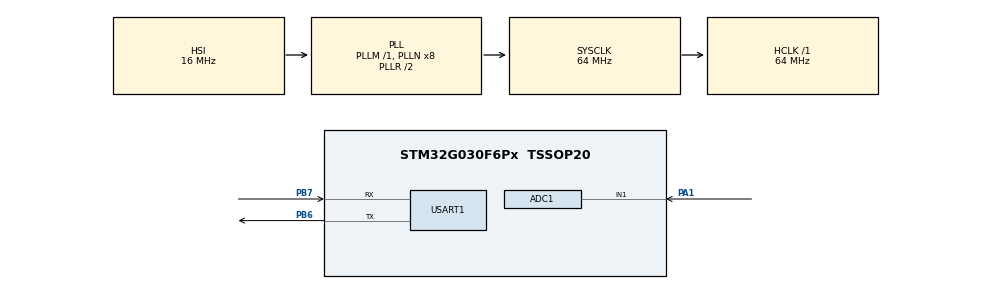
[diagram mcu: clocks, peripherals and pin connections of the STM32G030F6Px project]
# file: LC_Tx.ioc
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ADC1.Channel-2\#ChannelRegularConversion=ADC_CHANNEL_1
ADC1.ContinuousConvMode=ENABLE
ADC1.NbrOfConversionFlag=1
ADC1.Rank-2\#ChannelRegularConversion=1
ADC1.SamplingTime-2\#ChannelRegularConversion=ADC_SAMPLINGTIME_COMMON_1
ADC1.SelectedChannel=ADC_CHANNEL_1
ADC1.master=1
Mcu.Family=STM32G0
Mcu.Name=STM32G030F6Px
Mcu.Package=TSSOP20
PA1.Mode=IN1
PA1.Signal=ADC1_IN1
PA13.Mode=Serial_Wire
PA13.Signal=SYS_SWDIO
PA14-BOOT0.Mode=Serial_Wire
PA14-BOOT0.Signal=SYS_SWCLK
PA14-BOOT0__PA15.StandardMode=true
PB0__PB1__PB2__PA8.StandardMode=true
PB3__PB4__PB5__PB6.StandardMode=true
PB6.Mode=Asynchronous
PB6.Signal=USART1_TX
PB7.Mode=Asynchronous
PB7.Signal=USART1_RX
PB7__PB8.StandardMode=true
PC14-OSC32_IN\ (PC14)__PB9.StandardMode=true
ProjectManager.HeapSize=0x200
ProjectManager.StackSize=0x400
ProjectManager.TargetToolchain=STM32CubeIDE
RCC.ADCFreq_Value=64000000
RCC.AHBFreq_Value=64000000
RCC.CortexFreq_Value=64000000
RCC.EXTERNAL_CLOCK_VALUE=12288000
RCC.HCLKFreq_Value=64000000
RCC.HSE_VALUE=8000000
RCC.HSI_VALUE=16000000
RCC.LSE_VALUE=32768
RCC.SYSCLKFreq_VALUE=64000000
RCC.SYSCLKSource=RCC_SYSCLKSOURCE_PLLCLK
RCC.VCOOutputFreq_Value=128000000
USART1.VirtualMode-Asynchronous=VM_ASYNC
board=custom

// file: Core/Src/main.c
/* USER CODE BEGIN Header */
/**
  ******************************************************************************
  * @file           : main.c
  * @brief          : Main program body
  ******************************************************************************
  * @attention
  *
  * Copyright (c) 2023 STMicroelectronics.
  * All rights reserved.
  *
  * This software is licensed under terms that can be found in the LICENSE file
  * in the root directory of this software component.
  * If no LICENSE file comes with this software, it is provided AS-IS.
  *
  ******************************************************************************
  */
/* USER CODE END Header */
#include "main.h"

ADC_HandleTypeDef hadc1;

UART_HandleTypeDef huart1;

void SystemClock_Config(void);
static void MX_GPIO_Init(void);
static void MX_ADC1_Init(void);
static void MX_USART1_UART_Init(void);

int main(void)
{

  /* MCU Configuration--------------------------------------------------------*/

  /* Reset of all peripherals, Initializes the Flash interface and the Systick. */
  HAL_Init();

  /* Configure the system clock */
  SystemClock_Config();

  /* Initialize all configured peripherals */
  MX_GPIO_Init();
  MX_ADC1_Init();
  MX_USART1_UART_Init();
  /* USER CODE BEGIN 2 */
  HAL_ADCEx_Calibration_Start(&hadc1);
  HAL_ADC_Start(&hadc1);
  /* USER CODE END 2 */

  /* Infinite loop */
  while (1)
  {

    /* USER CODE BEGIN 3 */
//	  uint8_t Test[] = "Hello World !!!\r\n"; //Data to send
//	  HAL_UART_Transmit(&huart1,Test,sizeof(Test),10);// Sending in normal mode
//	  HAL_Delay(500);

	  HAL_ADC_PollForConversion(&hadc1, HAL_MAX_DELAY);
	  uint32_t value_adc = HAL_ADC_GetValue(&hadc1);
	  HAL_UART_Transmit(&huart1,(uint8_t*)&value_adc,sizeof(uint32_t),10);
	  HAL_Delay(100);
  }
  /* USER CODE END 3 */
}

void SystemClock_Config(void)
{
  RCC_OscInitTypeDef RCC_OscInitStruct = {0};
  RCC_ClkInitTypeDef RCC_ClkInitStruct = {0};

  /** Configure the main internal regulator output voltage
  */
  HAL_PWREx_ControlVoltageScaling(PWR_REGULATOR_VOLTAGE_SCALE1);

  /** Initializes the RCC Oscillators according to the specified parameters
  * in the RCC_OscInitTypeDef structure.
  */
  RCC_OscInitStruct.OscillatorType = RCC_OSCILLATORTYPE_HSI;
  RCC_OscInitStruct.HSIState = RCC_HSI_ON;
  RCC_OscInitStruct.HSIDiv = RCC_HSI_DIV1;
  RCC_OscInitStruct.HSICalibrationValue = RCC_HSICALIBRATION_DEFAULT;
  RCC_OscInitStruct.PLL.PLLState = RCC_PLL_ON;
  RCC_OscInitStruct.PLL.PLLSource = RCC_PLLSOURCE_HSI;
  RCC_OscInitStruct.PLL.PLLM = RCC_PLLM_DIV1;
  RCC_OscInitStruct.PLL.PLLN = 8;
  RCC_OscInitStruct.PLL.PLLP = RCC_PLLP_DIV2;
  RCC_OscInitStruct.PLL.PLLR = RCC_PLLR_DIV2;
  if (HAL_RCC_OscConfig(&RCC_OscInitStruct) != HAL_OK)
  {
    Error_Handler();
  }

  /** Initializes the CPU, AHB and APB buses clocks
  */
  RCC_ClkInitStruct.ClockType = RCC_CLOCKTYPE_HCLK|RCC_CLOCKTYPE_SYSCLK
                              |RCC_CLOCKTYPE_PCLK1;
  RCC_ClkInitStruct.SYSCLKSource = RCC_SYSCLKSOURCE_PLLCLK;
  RCC_ClkInitStruct.AHBCLKDivider = RCC_SYSCLK_DIV1;
  RCC_ClkInitStruct.APB1CLKDivider = RCC_HCLK_DIV1;

  if (HAL_RCC_ClockConfig(&RCC_ClkInitStruct, FLASH_LATENCY_2) != HAL_OK)
  {
    Error_Handler();
  }
}

static void MX_ADC1_Init(void)
{

  ADC_ChannelConfTypeDef sConfig = {0};

  /** Configure the global features of the ADC (Clock, Resolution, Data Alignment and number of conversion)
  */
  hadc1.Instance = ADC1;
  hadc1.Init.ClockPrescaler = ADC_CLOCK_SYNC_PCLK_DIV2;
  hadc1.Init.Resolution = ADC_RESOLUTION_12B;
  hadc1.Init.DataAlign = ADC_DATAALIGN_RIGHT;
  hadc1.Init.ScanConvMode = ADC_SCAN_DISABLE;
  hadc1.Init.EOCSelection = ADC_EOC_SINGLE_CONV;
  hadc1.Init.LowPowerAutoWait = DISABLE;
  hadc1.Init.LowPowerAutoPowerOff = DISABLE;
  hadc1.Init.ContinuousConvMode = ENABLE;
  hadc1.Init.NbrOfConversion = 1;
  hadc1.Init.ExternalTrigConv = ADC_SOFTWARE_START;
  hadc1.Init.ExternalTrigConvEdge = ADC_EXTERNALTRIGCONVEDGE_NONE;
  hadc1.Init.DMAContinuousRequests = DISABLE;
  hadc1.Init.Overrun = ADC_OVR_DATA_PRESERVED;
  hadc1.Init.SamplingTimeCommon1 = ADC_SAMPLETIME_1CYCLE_5;
  hadc1.Init.SamplingTimeCommon2 = ADC_SAMPLETIME_1CYCLE_5;
  hadc1.Init.OversamplingMode = DISABLE;
  hadc1.Init.TriggerFrequencyMode = ADC_TRIGGER_FREQ_HIGH;
  if (HAL_ADC_Init(&hadc1) != HAL_OK)
  {
    Error_Handler();
  }

  /** Configure Regular Channel
  */
  sConfig.Channel = ADC_CHANNEL_1;
  sConfig.Rank = ADC_REGULAR_RANK_1;
  sConfig.SamplingTime = ADC_SAMPLINGTIME_COMMON_1;
  if (HAL_ADC_ConfigChannel(&hadc1, &sConfig) != HAL_OK)
  {
    Error_Handler();
  }

}

static void MX_USART1_UART_Init(void)
{

  huart1.Instance = USART1;
  huart1.Init.BaudRate = 115200;
  huart1.Init.WordLength = UART_WORDLENGTH_8B;
  huart1.Init.StopBits = UART_STOPBITS_1;
  huart1.Init.Parity = UART_PARITY_NONE;
  huart1.Init.Mode = UART_MODE_TX_RX;
  huart1.Init.HwFlowCtl = UART_HWCONTROL_NONE;
  huart1.Init.OverSampling = UART_OVERSAMPLING_16;
  huart1.Init.OneBitSampling = UART_ONE_BIT_SAMPLE_DISABLE;
  huart1.Init.ClockPrescaler = UART_PRESCALER_DIV1;
  huart1.AdvancedInit.AdvFeatureInit = UART_ADVFEATURE_NO_INIT;
  if (HAL_UART_Init(&huart1) != HAL_OK)
  {
    Error_Handler();
  }
  if (HAL_UARTEx_SetTxFifoThreshold(&huart1, UART_TXFIFO_THRESHOLD_1_8) != HAL_OK)
  {
    Error_Handler();
  }
  if (HAL_UARTEx_SetRxFifoThreshold(&huart1, UART_RXFIFO_THRESHOLD_1_8) != HAL_OK)
  {
    Error_Handler();
  }
  if (HAL_UARTEx_DisableFifoMode(&huart1) != HAL_OK)
  {
    Error_Handler();
  }

}

static void MX_GPIO_Init(void)
{

  /* GPIO Ports Clock Enable */
  __HAL_RCC_GPIOB_CLK_ENABLE();
  __HAL_RCC_GPIOA_CLK_ENABLE();

}

void Error_Handler(void)
{
  __disable_irq();
  while (1)
  {
  }
}
